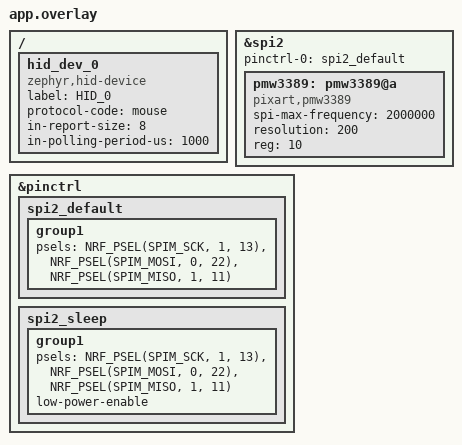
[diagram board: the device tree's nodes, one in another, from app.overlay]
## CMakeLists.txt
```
# Minimum required CMake version
cmake_minimum_required(VERSION 3.20.0)

# Find Zephyr package (must come before project())
find_package(Zephyr REQUIRED HINTS $ENV{ZEPHYR_BASE})

# Define your project
project(wireless_mouse VERSION 0.1.0)


target_sources(app PRIVATE src/main.c src/sensors/pmw3389/pmw3389.c)
```

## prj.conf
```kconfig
CONFIG_SPI=y

CONFIG_USBD_HID_SUPPORT=y

CONFIG_USB_DEVICE_STACK=y
CONFIG_USB_DEVICE_HID=y
CONFIG_USB_DEVICE_PRODUCT="Zephyr HID mouse sample"
CONFIG_USB_DEVICE_PID=0x0007
CONFIG_USB_DEVICE_INITIALIZE_AT_BOOT=n

CONFIG_LOG=y
CONFIG_USB_DRIVER_LOG_LEVEL_ERR=y
CONFIG_USB_DEVICE_LOG_LEVEL_ERR=y

CONFIG_GPIO=y
CONFIG_INPUT=y
CONFIG_INPUT_MODE_SYNCHRONOUS=y
```

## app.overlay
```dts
&spi2 {
    status = "okay";
    pinctrl-0 = <&spi2_default>;
    pinctrl-names = "default", "sleep";
    pmw3389: pmw3389@a {
        compatible = "pixart,pmw3389";
        spi-max-frequency = <2000000>; // 2MHz
        resolution = <200>; // overflow in 0.5s at 8m/s -> 200 CPI
        status = "okay";
        reg = <10>;
    };
};


/ {
    hid_dev_0: hid_dev_0 {
        compatible = "zephyr,hid-device";
        status = "okay";
        label = "HID_0";
        protocol-code = "mouse";
        in-report-size = <8>;
        in-polling-period-us = <1000>;
    };
};

&pinctrl {
    spi2_default: spi2_default {
            group1 {
                    psels = <NRF_PSEL(SPIM_SCK, 1, 13)>,
                            <NRF_PSEL(SPIM_MOSI, 0, 22)>,
                            <NRF_PSEL(SPIM_MISO, 1, 11)>;
            };
    };
    spi2_sleep: spi2_sleep {
            group1 {
                    psels = <NRF_PSEL(SPIM_SCK, 1, 13)>,
                            <NRF_PSEL(SPIM_MOSI, 0, 22)>,
                            <NRF_PSEL(SPIM_MISO, 1, 11)>;
                    low-power-enable;
            };
    };
};
```

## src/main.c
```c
#include "config.h"
#include <zephyr/kernel.h>
#include <zephyr/device.h>
#include <zephyr/usb/usb_device.h>
#include <zephyr/usb/class/usb_hid.h>
#include <zephyr/logging/log.h>
#include <zephyr/usb/class/usb_hid.h>

#include <zephyr/logging/log.h>
LOG_MODULE_REGISTER(main, LOG_LEVEL_INF);

static const uint8_t hid_report_desc[] = HID_MOUSE_REPORT_DESC(2);

enum mouse_report_idx {
	MOUSE_BTN_REPORT_ID = 0,
	MOUSE_X_REPORT_ID = 1,
	MOUSE_Y_REPORT_ID = 2,
	MOUSE_WHEEL_REPORT_ID = 3,
	MOUSE_REPORT_COUNT = 4,
};

const struct device *hid_dev;

static void status_cb(enum usb_dc_status_code status, const uint8_t *param) {
    LOG_INF("USB status: %d", status);
}
volatile short x = 0, y = 0;

int main(void) {
    int ret;

    hid_dev = device_get_binding("HID_0");


    if (!device_is_ready(hid_dev)) {
        LOG_ERR("HID device not ready");
        return -1;
    }

    ret = usb_enable(status_cb);
    if (ret) {
        LOG_ERR("Failed to enable USB");
        return -1;
    }

    usb_hid_register_device(hid_dev, hid_report_desc,
                                  sizeof(hid_report_desc), NULL);


    ret = usb_hid_init(hid_dev);
    if (ret) {
        LOG_ERR("Failed to initialize HID");
        return -1;
    }
    ret = init_pmw3389();

    uint8_t report[4] = {0};

    ret = hid_int_ep_write(hid_dev, report, sizeof(report), NULL);
    if (ret) {
        LOG_ERR("Failed to send mouse report: %d", ret);
    }

    while (1) {
        fetch_burst_xy(&x,  &y);
        report[MOUSE_X_REPORT_ID] = x;
        report[MOUSE_Y_REPORT_ID] = -y;
        hid_int_ep_write(hid_dev, report, sizeof(report), NULL);

        k_msleep(10);
    }

    return 0;
}
```

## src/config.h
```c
#ifndef CONFIG_H
#define CONFIG_H

#define PMW3389_SPI_DEV DEVICE_DT_GET(DT_NODELABEL(spi2))
#define PMW3389_CS_PIN 24

// doesn't account for gpio port WIP
#define LEFT_BUTTON_PIN  11
#define RIGHT_BUTTON_PIN 12
#define MIDDLE_BUTTON_PIN 13
#define MIDDLE_LEFT_BUTTON_PIN 14
#define MIDDLE_RIGHT_BUTTON_PIN 15
#define SCROLL_WHEEL_PIN 16

#include "sensors/pmw3389/pmw3389.h"



#endif // CONFIG_H
```

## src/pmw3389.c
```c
/* adapted from mrjohnk's https://github.com/mrjohnk/PMW3389DM/blob/master/Arduino%20Examples/PMW3389DM-polling/PMW3389DM-polling.ino
               and dkao's https://github.com/dkao/Kensington_Expert_Mouse_PMW3389_Arduino*/
#include "pmw3389.h"

static const struct device *pmw3389_spi_dev = DEVICE_DT_GET(DT_NODELABEL(PMW3389_SPI_DEV));
static const struct gpio_dt_spec cs = {
    .port = DEVICE_DT_GET(DT_NODELABEL(gpio0)),
    .pin = PMW3389_CS_PIN,
};

#define SPI_MODE_3 (SPI_MODE_CPOL | SPI_MODE_CPHA)

static struct spi_config pmw3389_spi_cfg = {
    .frequency = 2000000, // 4 MHz
    .operation =  SPI_WORD_SET(8) | SPI_TRANSFER_MSB | SPI_MODE_3 | SPI_OP_MODE_MASTER,
    .slave = 10,
};

#define R_CHECK(func) do { \
    int ret = (func); \
    if (ret) { \
        printk("Error in %s: %d\n", #func, ret); \
        return ret; \
    } \
} while (0)

void begin_ncs(void) {
    gpio_pin_set_dt(&cs, 0); // drive ncs low
}
 void end_ncs(void) {
    gpio_pin_set_dt(&cs, 1); // drive ncs high
}

int send_byte(uint8_t data) {
    uint8_t tx_buf[1] = {data};
    struct spi_buf tx_buffer = {.buf = tx_buf, .len = sizeof(tx_buf)};
    struct spi_buf_set tx_buffer_set = {.buffers = &tx_buffer, .count = 1};

    int ret = spi_write(pmw3389_spi_dev, &pmw3389_spi_cfg, &tx_buffer_set);
    if (ret) {
        printk("SPI write error: %d\n", ret);
    }
    return ret;
}

int receive_byte(uint8_t *data) {
    uint8_t tx_buf[1] = {0x00};
    uint8_t rx_buf[1] = {0};

    struct spi_buf tx = {.buf = tx_buf, .len = 1};
    struct spi_buf rx = {.buf = rx_buf, .len = 1};

    struct spi_buf_set tx_set = {.buffers = &tx, .count = 1};
    struct spi_buf_set rx_set = {.buffers = &rx, .count = 1};

    R_CHECK(spi_transceive(pmw3389_spi_dev, &pmw3389_spi_cfg, &tx_set, &rx_set));

    // Copy received data to output parameter

    *data = rx_buf[0];
    return 0;
}


int read_register(uint8_t reg) {
    begin_ncs();
    send_byte(reg & 0x7F); // MSB = 0 for read
    k_busy_wait(100);      // T_SRAD

    uint8_t data = 0;
    int ret = receive_byte(&data);

    k_busy_wait(1);  // T_SRX
    end_ncs();
    k_busy_wait(120); // T_BEXIT

    if (ret) {
        printk("SPI read failed for reg 0x%02X\n", reg);
        return -1;
    }

    return data;
}


int write_register(uint8_t reg, uint8_t data) {
    begin_ncs();
    uint8_t tx_buf[2] = {reg | 0x80, data};  // MSB = 1 for write
    struct spi_buf tx_buf_struct = {.buf = tx_buf, .len = 2};
    struct spi_buf_set tx_buf_set = {.buffers = &tx_buf_struct, .count = 1};

    int ret = spi_write(pmw3389_spi_dev, &pmw3389_spi_cfg, &tx_buf_set);
    if (ret) {
        printk("SPI write error: %d\n", ret);
    }

    k_busy_wait(20);
    end_ncs();
    k_busy_wait(120);
    return ret;
}

int read_burst(uint8_t *data, int len) {
    begin_ncs();
    send_byte(Motion_Burst);
    k_busy_wait(35);

    struct spi_buf rx = {.buf = data, .len = len};
    struct spi_buf_set rx_set = {.buffers = &rx, .count = 1};

    int ret = spi_read(pmw3389_spi_dev, &pmw3389_spi_cfg, &rx_set);
    end_ncs();
    k_busy_wait(120); // Post-burst wait

    return ret;
}

int fetch_burst_xy(volatile short *x, volatile short *y) {
    uint8_t tx_buf_data[12] = {0};         // Dummy bytes
    uint8_t rx_buf_data[12] = {0};


    struct spi_buf tx_buf = {
        .buf = tx_buf_data,
        .len = sizeof(tx_buf_data),
    };
    struct spi_buf rx_buf = {
        .buf = rx_buf_data,
        .len = sizeof(rx_buf_data),
    };
    struct spi_buf_set tx = {
        .buffers = &tx_buf,
        .count = 1,
    };
    struct spi_buf_set rx = {
        .buffers = &rx_buf,
        .count = 1,
    };

    // Start burst mode
    begin_ncs();

    if (send_byte(Motion_Burst)) {
        end_ncs();
        printk("Failed to send Motion_Burst command\n");
        return -EIO;
    }

    k_busy_wait(35); 


    // Transceive dummy bytes to get burst data
    int ret = spi_transceive(pmw3389_spi_dev, &pmw3389_spi_cfg, &tx, &rx);
    k_busy_wait(1);
    end_ncs();
    if (ret) return ret;
    /*
       Y+
    X-    X+
       Y-
    */


    *x = -(int16_t)((rx_buf_data[3] << 8) | rx_buf_data[2]);
    *y = (int16_t)((rx_buf_data[5] << 8) | rx_buf_data[4]);


    return 0;
}

int srom_download(const uint8_t *firmware_data, size_t firmware_length) {

    R_CHECK(write_register(Config2, 0x00));
    R_CHECK(write_register(SROM_Enable, 0x1D));

    k_msleep(10); // Wait for SROM to be enabled

    R_CHECK(write_register(SROM_Enable, 0x18));

    begin_ncs();
    send_byte(SROM_Load_Burst | 0x80); // Set MSB for SROM load burst
    k_busy_wait(15);

    for (int i = 0; i < firmware_length; i++) {
        send_byte(firmware_data[i]);
        k_busy_wait(15);
    }

    k_msleep(10); // Wait for SROM load to complete

    uint8_t srom_id = read_register(SROM_ID);
    printk("SROM ID: %02X\n", srom_id);

    R_CHECK(write_register(Config2, 0x00));

    R_CHECK(write_register(Config1, 0x15));

    end_ncs();

    k_msleep(10); // Wait for the sensor to stabilize after SROM load
    return 0; // Success
}

int init_pmw3389(void) {
    gpio_pin_configure_dt(&cs, GPIO_OUTPUT_HIGH); // Set to HIGH (inactive) by default
    // Reset the PMW3389
    end_ncs();
    begin_ncs();
    end_ncs();

    R_CHECK(write_register(Shutdown, 0xB6)); // Power up reset
    k_msleep(300); // Wait for the sensor to power up

    begin_ncs();
    k_busy_wait(40);
    end_ncs();
    k_busy_wait(40);

    R_CHECK(write_register(Power_Up_Reset, 0x5A));
    k_msleep(50); // Wait for the sensor to reset

    // read registers 0x02 to 0x06
    uint8_t reg_data[5];
    reg_data[0] = read_register(Motion);
    reg_data[1] = read_register(Delta_X_L);
    reg_data[2] = read_register(Delta_X_H);
    reg_data[3] = read_register(Delta_Y_L);
    reg_data[4] = read_register(Delta_Y_H);

    /* SROM DONWLOAD
       for some reason loading SROM makes it so that the x and y regs are 0
       always 0 so its not needed in this case, YMMV
    END SROM DOWNLOAD */

    k_msleep(10);

    return 0; // Success
}
```

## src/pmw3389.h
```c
#ifndef PMW3389_H
#define PMW3389_H

#include "config.h"

#include <zephyr/drivers/spi.h>
#include <zephyr/logging/log.h>
#include <zephyr/sys/__assert.h>
#include <zephyr/kernel.h>
#include "srom.h"

// Pins
#ifndef PMW3389_CS_PIN
#define PMW3389_CS_PIN 24 // Default Chip Select pin, can be overridden in the build configuration
#endif

#ifndef PMW3389_SPI_DEV
#define PMW3389_SPI_DEV spi0 // Default SPI device, can be overridden in the build configuration
#endif



// Registers
#define Product_ID  0x00
#define Revision_ID 0x01
#define Motion  0x02
#define Delta_X_L 0x03
#define Delta_X_H 0x04
#define Delta_Y_L 0x05
#define Delta_Y_H 0x06
#define SQUAL 0x07
#define Raw_Data_Sum  0x08
#define Maximum_Raw_data  0x09
#define Minimum_Raw_data  0x0A
#define Shutter_Lower 0x0B
#define Shutter_Upper 0x0C
#define Control 0x0D
#define Config1 0x0F
#define Config2 0x10
#define Angle_Tune  0x11
#define Frame_Capture 0x12
#define SROM_Enable 0x13
#define Run_Downshift 0x14
#define Rest1_Rate_Lower  0x15
#define Rest1_Rate_Upper  0x16
#define Rest1_Downshift 0x17
#define Rest2_Rate_Lower  0x18
#define Rest2_Rate_Upper  0x19
#define Rest2_Downshift 0x1A
#define Rest3_Rate_Lower  0x1B
#define Rest3_Rate_Upper  0x1C
#define Observation 0x24
#define Data_Out_Lower  0x25
#define Data_Out_Upper  0x26
#define Raw_Data_Dump 0x29
#define SROM_ID 0x2A
#define Min_SQ_Run  0x2B
#define Raw_Data_Threshold  0x2C
#define Config5 0x2F
#define Power_Up_Reset  0x3A
#define Shutdown  0x3B
#define Inverse_Product_ID  0x3F
#define LiftCutoff_Tune3  0x41
#define Angle_Snap  0x42
#define LiftCutoff_Tune1  0x4A
#define Motion_Burst  0x50
#define LiftCutoff_Tune_Timeout 0x58
#define LiftCutoff_Tune_Min_Length  0x5A
#define SROM_Load_Burst 0x62
#define Lift_Config 0x63
#define Raw_Data_Burst  0x64
#define LiftCutoff_Tune2  0x65

#define constrain(x, a, b) ((x) < (a) ? (a) : ((x) > (b) ? (b) : (x)))

#define R_CHECK(func) do { \
    int ret = (func); \
    if (ret) { \
        printk("Error in %s: %d\n", #func, ret); \
        return ret; \
    } \
} while (0)

void begin_ncs(void);
void end_ncs(void);

int send_byte(uint8_t data);
int receive_byte(uint8_t *data);
int read_register(uint8_t reg);
int write_register(uint8_t reg, uint8_t value);
int srom_download(const uint8_t *firmware_data, size_t firmware_length);
int init_pmw3389(void);
int fetch_burst_xy(volatile short *x, volatile short *y);

static const struct device *pmw3389_spi_dev;
static struct spi_config pmw3389_spi_cfg;



#endif // PMW3389_H
```

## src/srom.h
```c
/* https://github.com/mrjohnk/PMW3389DM/blob/master/Arduino%20Examples/PMW3389DM-polling/SROM.ino */

// the firmeware that is uploaded in the ADNS each time it boots
#ifndef SROM_H
#define SROM_H
#include <stdint.h>

extern const unsigned short firmware_length;

extern const uint8_t firmware_data[];

#endif // SRC_SROM_H
```
